# MSP430FR5739 register map
File version: 1.1
CPU: msp430
Registers are 16-bit, access not given, reset 0x0 unless marked. A register's access mark holds for its fields unless they carry their own. Offsets are from the block's base; [hi:lo] are bit positions; {n}, {i} and the like mark numbered series.

## FRAM
Base 0x00000000
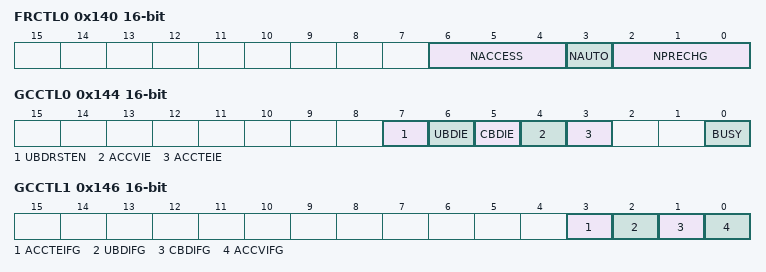
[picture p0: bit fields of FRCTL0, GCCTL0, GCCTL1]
0x140 FRCTL0 — FRAM Controller Control 0
  [6:4] NACCESS — [6:4] FRAM Wait state Generator Access Time control Bit: 0
    {v}=FRAM Wait state Generator Access Time control: {v} (v=0..7)
  [3] NAUTO — [3:3] FRAM Disables the wait state generator
  [2:0] NPRECHG — [2:0] FRAM Wait state Generator Precharge Time control Bit: 0
    {v}=FRAM Wait state Generator Precharge Time control: {v} (v=0..7)
0x144 GCCTL0 — General Control 0
  [7] UBDRSTEN — [7:7] Enable Power Up Clear on uncorrectable bit error
  [6] UBDIE — [6:6] Enable NMI event if uncorrectable bit error detected
  [5] CBDIE — [5:5] Enable NMI event if correctable bit error detected
  [4] ACCVIE — [4:4] Enable NMI event if Access Violation occurs
  [3] ACCTEIE — [3:3] Enable NMI event if Access time error occurs
  [0] BUSY — [0:0] FRAM is currently busy programming
0x146 GCCTL1 — General Control 1
  [3] ACCTEIFG — [3:3] Access time error flag
  [2] UBDIFG — [2:2] FRAM uncorrectable bit error flag
  [1] CBDIFG — [1:1] FRAM correctable bit error flag
  [0] ACCVIFG — [0:0] Access Violation Interrupt Flag

## MPU
Base 0x00000000
0x5A0 MPUCTL0 — MPU Control Register 0
  [0] MPUENA — [0:0] MPU Enable
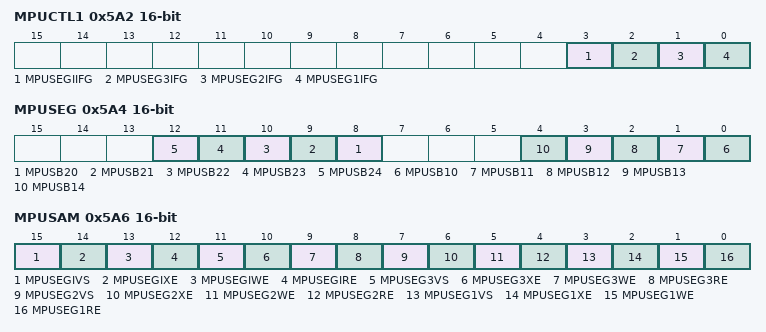
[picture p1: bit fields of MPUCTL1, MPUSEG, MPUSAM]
0x5A2 MPUCTL1 — MPU Control Register 1
  [3] MPUSEGIIFG — [3:3] MPU Info Memory Segment violation interupt flag
  [2] MPUSEG3IFG — [2:2] MPU Main Memory Segment 3 violation interupt flag
  [1] MPUSEG2IFG — [1:1] MPU Main Memory Segment 2 violation interupt flag
  [0] MPUSEG1IFG — [0:0] MPU Main Memory Segment 1 violation interupt flag
0x5A4 MPUSEG — MPU Segmentation Register
  [n-12] MPUSB{n} (n=20..24) — [{n-12}:{n-12}] MPU Segment Border 2 Bit: {n-20}
  [n-10] MPUSB{n} (n=10..14) — [{n-10}:{n-10}] MPU Segment Border 1 Bit: {n-10}
0x5A6 MPUSAM — MPU Access Management Register
  [15] MPUSEGIVS — [15:15] MPU Info memory Segment Violation select
  [14] MPUSEGIXE — [14:14] MPU Info memory Segment Execute enable
  [13] MPUSEGIWE — [13:13] MPU Info memory Segment Write enable
  [12] MPUSEGIRE — [12:12] MPU Info memory Segment Read enable
  [11] MPUSEG3VS — [11:11] MPU Main memory Segment 3 Violation select
  [10] MPUSEG3XE — [10:10] MPU Main memory Segment 3 Execute enable
  [9] MPUSEG3WE — [9:9] MPU Main memory Segment 3 Write enable
  [8] MPUSEG3RE — [8:8] MPU Main memory Segment 3 Read enable
  [7] MPUSEG2VS — [7:7] MPU Main memory Segment 2 Violation select
  [6] MPUSEG2XE — [6:6] MPU Main memory Segment 2 Execute enable
  [5] MPUSEG2WE — [5:5] MPU Main memory Segment 2 Write enable
  [4] MPUSEG2RE — [4:4] MPU Main memory Segment 2 Read enable
  [3] MPUSEG1VS — [3:3] MPU Main memory Segment 1 Violation select
  [2] MPUSEG1XE — [2:2] MPU Main memory Segment 1 Execute enable
  [1] MPUSEG1WE — [1:1] MPU Main memory Segment 1 Write enable
  [0] MPUSEG1RE — [0:0] MPU Main memory Segment 1 Read enable

## MPY_16__Multiplier__16_Bit_Mode
Base 0x00000000
0x4C0 MPY — Multiply Unsigned/Operand 1
0x4C2 MPYS — Multiply Signed/Operand 1
0x4C4 MAC — Multiply Unsigned and Accumulate/Operand 1
0x4C6 MACS — Multiply Signed and Accumulate/Operand 1
0x4C8 OP2 — Operand 2
0x4CA RESLO — Result Low Word
0x4CC RESHI — Result High Word
0x4CE SUMEXT — Sum Extend
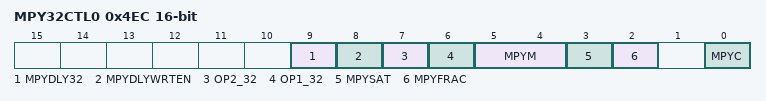
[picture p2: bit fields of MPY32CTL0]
0x4EC MPY32CTL0 — MPY32 Control Register 0
  [9] MPYDLY32 — [9:9] Delayed write mode
  [8] MPYDLYWRTEN — [8:8] Delayed write enable
  [7] OP2_32 — [7:7] Bit-width of operand 2 0:16Bit / 1:32Bit
  [6] OP1_32 — [6:6] Bit-width of operand 1 0:16Bit / 1:32Bit
  [5:4] MPYM — [5:4] Multiplier mode Bit:0
    0=Multiplier mode: MPY; 1=Multiplier mode: MPYS; 2=Multiplier mode: MAC; 3=Multiplier mode: MACS
  [3] MPYSAT — [3:3] Saturation mode
  [2] MPYFRAC — [2:2] Fractional mode
  [0] MPYC — [0:0] Carry of the multiplier
